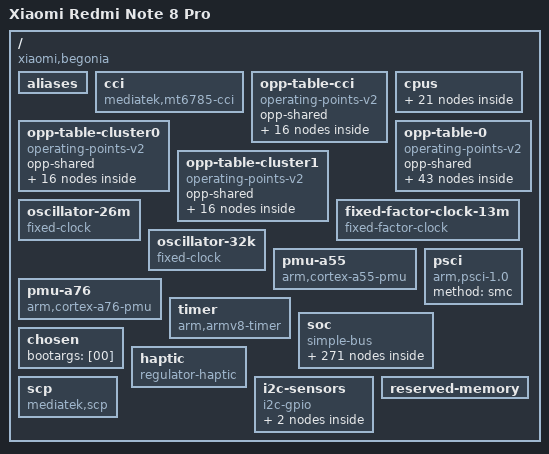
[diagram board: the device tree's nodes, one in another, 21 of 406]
/dts-v1/;

/ {
	#address-cells = <0x02>;
	#size-cells = <0x02>;
	interrupt-parent = <0x01>;
	model = "Xiaomi Redmi Note 8 Pro";
	compatible = "xiaomi,begonia", "mediatek,mt6785";
	chassis-type = "handset";

	aliases {
		ovl0 = "/soc/ovl@14008000";
		ovl-2l0 = "/soc/ovl@14009000";
		ovl-2l1 = "/soc/ovl@1400a000";
		rdma0 = "/soc/rdma@1400b000";
		rdma1 = "/soc/rdma@1400c000";
	};

	cci {
		compatible = "mediatek,mt6785-cci", "mediatek,mt8186-cci";
		clocks = <0x02 0x02 0x03 0x80>;
		clock-names = "cci", "intermediate";
		operating-points-v2 = <0x04>;
		proc-supply = <0x05>;
		phandle = <0x20>;
	};

	opp-table-cci {
		compatible = "operating-points-v2";
		opp-shared;
		phandle = <0x04>;

		opp-500000000 {
			opp-hz = <0x00 0x1dcd6500>;
			opp-microvolt = <0x927c0>;
			phandle = <0x06>;
		};

		opp-560000000 {
			opp-hz = <0x00 0x2160ec00>;
			opp-microvolt = <0xa4cb8>;
			phandle = <0x07>;
		};

		opp-612000000 {
			opp-hz = <0x00 0x247a6100>;
			opp-microvolt = <0xa95f6>;
			phandle = <0x08>;
		};

		opp-682000000 {
			opp-hz = <0x00 0x28a67e80>;
			opp-microvolt = <0xaf79e>;
			phandle = <0x09>;
		};

		opp-752000000 {
			opp-hz = <0x00 0x2cd29c00>;
			opp-microvolt = <0xb5946>;
			phandle = <0x0a>;
		};

		opp-822000000 {
			opp-hz = <0x00 0x30feb980>;
			opp-microvolt = <0xbbaee>;
			phandle = <0x0b>;
		};

		opp-875000000 {
			opp-hz = <0x00 0x342770c0>;
			opp-microvolt = <0xbebc2>;
			phandle = <0x0c>;
		};

		opp-927000000 {
			opp-hz = <0x00 0x3740e5c0>;
			opp-microvolt = "", "\f5";
			phandle = <0x0d>;
		};

		opp-980000000 {
			opp-hz = <0x00 0x3a699d00>;
			opp-microvolt = <0xc7e3e>;
			phandle = <0x0e>;
		};

		opp-1050000000 {
			opp-hz = <0x00 0x3e95ba80>;
			opp-microvolt = <0xcdfe6>;
			phandle = <0x0f>;
		};

		opp-1120000000 {
			opp-hz = <0x00 0x42c1d800>;
			opp-microvolt = <0xd2924>;
			phandle = <0x10>;
		};

		opp-1155000000 {
			opp-hz = <0x00 0x44d7e6c0>;
			opp-microvolt = <0xd8acc>;
			phandle = <0x11>;
		};

		opp-1190000000 {
			opp-hz = <0x00 0x46edf580>;
			opp-microvolt = <0xdd40a>;
			phandle = <0x12>;
		};

		opp-1260000000 {
			opp-hz = <0x00 0x4b1a1300>;
			opp-microvolt = <0xe7ef0>;
			phandle = <0x13>;
		};

		opp-1330000000 {
			opp-hz = <0x00 0x4f463080>;
			opp-microvolt = <0xf29d6>;
			phandle = <0x14>;
		};

		opp-1400000000 {
			opp-hz = <0x00 0x53724e00>;
			opp-microvolt = <0xfbc52>;
			phandle = <0x15>;
		};
	};

	opp-table-cluster0 {
		compatible = "operating-points-v2";
		opp-shared;
		phandle = <0x1e>;

		opp-500000000 {
			opp-hz = <0x00 0x1dcd6500>;
			opp-microvolt = <0x927c0>;
			required-opps = <0x06>;
		};

		opp-774000000 {
			opp-hz = <0x00 0x2e224d80>;
			opp-microvolt = <0xa4cb8>;
			required-opps = <0x07>;
		};

		opp-875000000 {
			opp-hz = <0x00 0x342770c0>;
			opp-microvolt = <0xaae60>;
			required-opps = <0x08>;
		};

		opp-975000000 {
			opp-hz = <0x00 0x3a1d51c0>;
			opp-microvolt = <0xb1008>;
			required-opps = <0x09>;
		};

		opp-1075000000 {
			opp-hz = <0x00 0x401332c0>;
			opp-microvolt = <0xb71b0>;
			required-opps = <0x0a>;
		};

		opp-1175000000 {
			opp-hz = <0x00 0x460913c0>;
			opp-microvolt = <0xbd358>;
			required-opps = <0x0b>;
		};

		opp-1275000000 {
			opp-hz = <0x00 0x4bfef4c0>;
			opp-microvolt = "", "\f5";
			required-opps = <0x0c>;
		};

		opp-1375000000 {
			opp-hz = <0x00 0x51f4d5c0>;
			opp-microvolt = <0xc96a8>;
			required-opps = <0x0d>;
		};

		opp-1500000000 {
			opp-hz = <0x00 0x59682f00>;
			opp-microvolt = <0xd10ba>;
			required-opps = <0x0e>;
		};

		opp-1618000000 {
			opp-hz = <0x00 0x6070b880>;
			opp-microvolt = <0xd59f8>;
			required-opps = <0x0f>;
		};

		opp-1666000000 {
			opp-hz = <0x00 0x634d2480>;
			opp-microvolt = <0xdbba0>;
			required-opps = <0x10>;
		};

		opp-1733000000 {
			opp-hz = <0x00 0x674b7b40>;
			opp-microvolt = <0xe1d48>;
			required-opps = <0x11>;
		};

		opp-1800000000 {
			opp-hz = <0x00 0x6b49d200>;
			opp-microvolt = <0xe7ef0>;
			required-opps = <0x12>;
		};

		opp-1866000000 {
			opp-hz = <0x00 0x6f38e680>;
			opp-microvolt = <0xef902>;
			required-opps = <0x13>;
		};

		opp-1933000000 {
			opp-hz = <0x00 0x73373d40>;
			opp-microvolt = <0xf5aaa>;
			required-opps = <0x14>;
		};

		opp-2000000000 {
			opp-hz = <0x00 0x77359400>;
			opp-microvolt = <0xfbc52>;
			required-opps = <0x15>;
		};
	};

	opp-table-cluster1 {
		compatible = "operating-points-v2";
		opp-shared;
		phandle = <0x21>;

		opp-774000000 {
			opp-hz = <0x00 0x2e224d80>;
			opp-microvolt = <0xa4cb8>;
			required-opps = <0x06>;
		};

		opp-835000000 {
			opp-hz = <0x00 0x31c516c0>;
			opp-microvolt = <0xa95f6>;
			required-opps = <0x07>;
		};

		opp-919000000 {
			opp-hz = <0x00 0x36c6d3c0>;
			opp-microvolt = <0xaf79e>;
			required-opps = <0x08>;
		};

		opp-1002000000 {
			opp-hz = <0x00 0x3bb94e80>;
			opp-microvolt = <0xb5946>;
			required-opps = <0x09>;
		};

		opp-1085000000 {
			opp-hz = <0x00 0x40abc940>;
			opp-microvolt = <0xbd358>;
			required-opps = <0x0a>;
		};

		opp-1169000000 {
			opp-hz = <0x00 0x45ad8640>;
			opp-microvolt = "", "\f5";
			required-opps = <0x0b>;
		};

		opp-1308000000 {
			opp-hz = <0x00 0x4df67f00>;
			opp-microvolt = <0xcdfe6>;
			required-opps = <0x0c>;
		};

		opp-1419000000 {
			opp-hz = <0x00 0x549438c0>;
			opp-microvolt = <0xd59f8>;
			required-opps = <0x0d>;
		};

		opp-1530000000 {
			opp-hz = <0x00 0x5b31f280>;
			opp-microvolt = <0xdec74>;
			required-opps = <0x0e>;
		};

		opp-1670000000 {
			opp-hz = <0x00 0x638a2d80>;
			opp-microvolt = <0xe975a>;
			required-opps = <0x0f>;
		};

		opp-1733000000 {
			opp-hz = <0x00 0x674b7b40>;
			opp-microvolt = <0xef902>;
			required-opps = <0x10>;
		};

		opp-1796000000 {
			opp-hz = <0x00 0x6b0cc900>;
			opp-microvolt = <0xf7314>;
			required-opps = <0x11>;
		};

		opp-1860000000 {
			opp-hz = <0x00 0x6edd5900>;
			opp-microvolt = <0xfd4bc>;
			required-opps = <0x12>;
		};

		opp-1923000000 {
			opp-hz = <0x00 0x729ea6c0>;
			opp-microvolt = <0x103664>;
			required-opps = <0x13>;
		};

		opp-1986000000 {
			opp-hz = <0x00 0x765ff480>;
			opp-microvolt = <0x10b076>;
			required-opps = <0x14>;
		};

		opp-2050000000 {
			opp-hz = <0x00 0x7a308480>;
			opp-microvolt = <0x11121e>;
			required-opps = <0x15>;
		};
	};

	cpus {
		#address-cells = <0x01>;
		#size-cells = <0x00>;

		cpu-map {

			cluster0 {

				core0 {
					cpu = <0x16>;
				};

				core1 {
					cpu = <0x17>;
				};

				core2 {
					cpu = <0x18>;
				};

				core3 {
					cpu = <0x19>;
				};

				core4 {
					cpu = <0x1a>;
				};

				core5 {
					cpu = <0x1b>;
				};

				core6 {
					cpu = <0x1c>;
				};

				core7 {
					cpu = <0x1d>;
				};
			};
		};

		cpu@0 {
			device_type = "cpu";
			compatible = "arm,cortex-a55";
			reg = <0x00>;
			enable-method = "psci";
			clocks = <0x02 0x00 0x03 0x80>;
			clock-names = "cpu", "intermediate";
			operating-points-v2 = <0x1e>;
			dynamic-power-coefficient = <0x54>;
			capacity-dmips-mhz = <0x11c>;
			i-cache-size = <0x8000>;
			i-cache-line-size = <0x40>;
			i-cache-sets = <0x80>;
			d-cache-size = <0x8000>;
			d-cache-line-size = <0x40>;
			d-cache-sets = <0x80>;
			next-level-cache = <0x1f>;
			mediatek,cci = <0x20>;
			proc-supply = <0x05>;
			phandle = <0x16>;
		};

		cpu@100 {
			device_type = "cpu";
			compatible = "arm,cortex-a55";
			reg = <0x100>;
			enable-method = "psci";
			clocks = <0x02 0x00 0x03 0x80>;
			clock-names = "cpu", "intermediate";
			operating-points-v2 = <0x1e>;
			dynamic-power-coefficient = <0x54>;
			capacity-dmips-mhz = <0x11c>;
			i-cache-size = <0x8000>;
			i-cache-line-size = <0x40>;
			i-cache-sets = <0x80>;
			d-cache-size = <0x8000>;
			d-cache-line-size = <0x40>;
			d-cache-sets = <0x80>;
			next-level-cache = <0x1f>;
			mediatek,cci = <0x20>;
			proc-supply = <0x05>;
			phandle = <0x17>;
		};

		cpu@200 {
			device_type = "cpu";
			compatible = "arm,cortex-a55";
			reg = <0x200>;
			enable-method = "psci";
			clocks = <0x02 0x00 0x03 0x80>;
			clock-names = "cpu", "intermediate";
			operating-points-v2 = <0x1e>;
			dynamic-power-coefficient = <0x54>;
			capacity-dmips-mhz = <0x11c>;
			i-cache-size = <0x8000>;
			i-cache-line-size = <0x40>;
			i-cache-sets = <0x80>;
			d-cache-size = <0x8000>;
			d-cache-line-size = <0x40>;
			d-cache-sets = <0x80>;
			next-level-cache = <0x1f>;
			mediatek,cci = <0x20>;
			proc-supply = <0x05>;
			phandle = <0x18>;
		};

		cpu@300 {
			device_type = "cpu";
			compatible = "arm,cortex-a55";
			reg = <0x300>;
			enable-method = "psci";
			clocks = <0x02 0x00 0x03 0x80>;
			clock-names = "cpu", "intermediate";
			operating-points-v2 = <0x1e>;
			dynamic-power-coefficient = <0x54>;
			capacity-dmips-mhz = <0x11c>;
			i-cache-size = <0x8000>;
			i-cache-line-size = <0x40>;
			i-cache-sets = <0x80>;
			d-cache-size = <0x8000>;
			d-cache-line-size = <0x40>;
			d-cache-sets = <0x80>;
			next-level-cache = <0x1f>;
			mediatek,cci = <0x20>;
			proc-supply = <0x05>;
			phandle = <0x19>;
		};

		cpu@400 {
			device_type = "cpu";
			compatible = "arm,cortex-a55";
			reg = <0x400>;
			enable-method = "psci";
			clocks = <0x02 0x00 0x03 0x80>;
			clock-names = "cpu", "intermediate";
			operating-points-v2 = <0x1e>;
			dynamic-power-coefficient = <0x54>;
			capacity-dmips-mhz = <0x11c>;
			i-cache-size = <0x8000>;
			i-cache-line-size = <0x40>;
			i-cache-sets = <0x80>;
			d-cache-size = <0x8000>;
			d-cache-line-size = <0x40>;
			d-cache-sets = <0x80>;
			next-level-cache = <0x1f>;
			mediatek,cci = <0x20>;
			proc-supply = <0x05>;
			phandle = <0x1a>;
		};

		cpu@500 {
			device_type = "cpu";
			compatible = "arm,cortex-a55";
			reg = <0x500>;
			enable-method = "psci";
			clocks = <0x02 0x00 0x03 0x80>;
			clock-names = "cpu", "intermediate";
			operating-points-v2 = <0x1e>;
			dynamic-power-coefficient = <0x54>;
			capacity-dmips-mhz = <0x11c>;
			i-cache-size = <0x8000>;
			i-cache-line-size = <0x40>;
			i-cache-sets = <0x80>;
			d-cache-size = <0x8000>;
			d-cache-line-size = <0x40>;
			d-cache-sets = <0x80>;
			next-level-cache = <0x1f>;
			mediatek,cci = <0x20>;
			proc-supply = <0x05>;
			phandle = <0x1b>;
		};

		cpu@600 {
			device_type = "cpu";
			compatible = "arm,cortex-a76";
			reg = <0x600>;
			enable-method = "psci";
			clocks = <0x02 0x01 0x03 0x80>;
			clock-names = "cpu", "intermediate";
			operating-points-v2 = <0x21>;
			dynamic-power-coefficient = <0x113>;
			capacity-dmips-mhz = <0x400>;
			i-cache-size = <0x10000>;
			i-cache-line-size = <0x40>;
			i-cache-sets = <0x100>;
			d-cache-size = <0x10000>;
			d-cache-line-size = <0x40>;
			d-cache-sets = <0x100>;
			next-level-cache = <0x22>;
			mediatek,cci = <0x20>;
			proc-supply = <0x23>;
			phandle = <0x1c>;
		};

		cpu@700 {
			device_type = "cpu";
			compatible = "arm,cortex-a76";
			reg = <0x700>;
			enable-method = "psci";
			clocks = <0x02 0x01 0x03 0x80>;
			clock-names = "cpu", "intermediate";
			operating-points-v2 = <0x21>;
			dynamic-power-coefficient = <0x113>;
			capacity-dmips-mhz = <0x400>;
			i-cache-size = <0x10000>;
			i-cache-line-size = <0x40>;
			i-cache-sets = <0x100>;
			d-cache-size = <0x10000>;
			d-cache-line-size = <0x40>;
			d-cache-sets = <0x100>;
			next-level-cache = <0x22>;
			mediatek,cci = <0x20>;
			proc-supply = <0x23>;
			phandle = <0x1d>;
		};

		l2-cache0 {
			compatible = "cache";
			cache-level = <0x02>;
			cache-size = <0x20000>;
			cache-line-size = <0x40>;
			cache-sets = <0x200>;
			next-level-cache = <0x24>;
			cache-unified;
			phandle = <0x1f>;
		};

		l2-cache1 {
			compatible = "cache";
			cache-level = <0x02>;
			cache-size = <0x40000>;
			cache-line-size = <0x40>;
			cache-sets = <0x200>;
			next-level-cache = <0x24>;
			cache-unified;
			phandle = <0x22>;
		};

		l3-cache {
			compatible = "cache";
			cache-level = <0x03>;
			cache-size = <0x100000>;
			cache-line-size = <0x40>;
			cache-sets = <0x400>;
			cache-unified;
			phandle = <0x24>;
		};
	};

	opp-table-0 {
		compatible = "operating-points-v2";
		opp-shared;
		phandle = <0x54>;

		opp-270000000 {
			opp-hz = <0x00 0x1017df80>;
			opp-microvolt = <0x95894>;
		};

		opp-295000000 {
			opp-hz = <0x00 0x119557c0>;
			opp-microvolt = <0x970fe>;
		};

		opp-320000000 {
			opp-hz = <0x00 0x1312d000>;
			opp-microvolt = <0x98968>;
		};

		opp-345000000 {
			opp-hz = <0x00 0x14904840>;
			opp-microvolt = <0x9a1d2>;
		};

		opp-370000000 {
			opp-hz = <0x00 0x160dc080>;
			opp-microvolt = <0x9ba3c>;
		};

		opp-395000000 {
			opp-hz = <0x00 0x178b38c0>;
			opp-microvolt = <0x9d2a6>;
		};

		opp-420000000 {
			opp-hz = <0x00 0x1908b100>;
			opp-microvolt = <0x9eb10>;
		};

		opp-445000000 {
			opp-hz = <0x00 0x1a862940>;
			opp-microvolt = <0xa037a>;
		};

		opp-470000000 {
			opp-hz = <0x00 0x1c03a180>;
			opp-microvolt = <0xa1be4>;
		};

		opp-495000000 {
			opp-hz = <0x00 0x1d8119c0>;
			opp-microvolt = <0xa344e>;
		};

		opp-520000000 {
			opp-hz = <0x00 0x1efe9200>;
			opp-microvolt = <0xa4cb8>;
		};

		opp-545000000 {
			opp-hz = <0x00 0x207c0a40>;
			opp-microvolt = <0xa6522>;
		};

		opp-570000000 {
			opp-hz = <0x00 0x21f98280>;
			opp-microvolt = <0xa7d8c>;
		};

		opp-595000000 {
			opp-hz = <0x00 0x2376fac0>;
			opp-microvolt = <0xa95f6>;
		};

		opp-620000000 {
			opp-hz = <0x00 0x24f47300>;
			opp-microvolt = <0xaae60>;
		};

		opp-634000000 {
			opp-hz = <0x00 0x25ca1280>;
			opp-microvolt = <0xac6ca>;
		};

		opp-648000000 {
			opp-hz = <0x00 0x269fb200>;
			opp-microvolt = <0xadf34>;
		};

		opp-663000000 {
			opp-hz = <0x00 0x278493c0>;
			opp-microvolt = <0xaf79e>;
		};

		opp-677000000 {
			opp-hz = <0x00 0x285a3340>;
			opp-microvolt = <0xb1008>;
		};

		opp-691000000 {
			opp-hz = <0x00 0x292fd2c0>;
			opp-microvolt = <0xb2872>;
		};

		opp-706000000 {
			opp-hz = <0x00 0x2a14b480>;
			opp-microvolt = <0xb40dc>;
		};

		opp-720000000 {
			opp-hz = <0x00 0x2aea5400>;
			opp-microvolt = <0xb5946>;
		};

		opp-735000000 {
			opp-hz = <0x00 0x2bcf35c0>;
			opp-microvolt = <0xb71b0>;
		};

		opp-749000000 {
			opp-hz = <0x00 0x2ca4d540>;
			opp-microvolt = <0xb8a1a>;
		};

		opp-763000000 {
			opp-hz = <0x00 0x2d7a74c0>;
			opp-microvolt = <0xba284>;
		};

		opp-778000000 {
			opp-hz = <0x00 0x2e5f5680>;
			opp-microvolt = <0xbbaee>;
		};

		opp-792000000 {
			opp-hz = <0x00 0x2f34f600>;
			opp-microvolt = <0xbd358>;
		};

		opp-806000000 {
			opp-hz = <0x00 0x300a9580>;
			opp-microvolt = <0xbebc2>;
		};

		opp-821000000 {
			opp-hz = <0x00 0x30ef7740>;
			opp-microvolt = <0xc042c>;
		};

		opp-835000000 {
			opp-hz = <0x00 0x31c516c0>;
			opp-microvolt = <0xc1c96>;
		};

		opp-850000000 {
			opp-hz = <0x00 0x32a9f880>;
			opp-microvolt = "", "\f5";
		};

		opp-854000000 {
			opp-hz = <0x00 0x32e70180>;
			opp-microvolt = <0xc4d6a>;
		};

		opp-858000000 {
			opp-hz = <0x00 0x33240a80>;
			opp-microvolt = <0xc65d4>;
		};

		opp-862000000 {
			opp-hz = <0x00 0x33611380>;
			opp-microvolt = <0xc7e3e>;
		};

		opp-867000000 {
			opp-hz = <0x00 0x33ad5ec0>;
			opp-microvolt = <0xc96a8>;
		};

		opp-871000000 {
			opp-hz = <0x00 0x33ea67c0>;
			opp-microvolt = <0xcaf12>;
		};

		opp-875000000 {
			opp-hz = <0x00 0x342770c0>;
			opp-microvolt = <0xcc77c>;
		};

		opp-880000000 {
			opp-hz = <0x00 0x3473bc00>;
			opp-microvolt = <0xcdfe6>;
		};

		opp-884000000 {
			opp-hz = <0x00 0x34b0c500>;
			opp-microvolt = <0xcf850>;
		};

		opp-888000000 {
			opp-hz = <0x00 0x34edce00>;
			opp-microvolt = <0xd10ba>;
		};

		opp-892000000 {
			opp-hz = <0x00 0x352ad700>;
			opp-microvolt = <0xd2924>;
		};

		opp-897000000 {
			opp-hz = <0x00 0x35772240>;
			opp-microvolt = <0xd418e>;
		};

		opp-900000000 {
			opp-hz = <0x00 0x35a4e900>;
			opp-microvolt = <0xd59f8>;
		};
	};

	fixed-factor-clock-13m {
		compatible = "fixed-factor-clock";
		#clock-cells = <0x00>;
		clocks = <0x25>;
		clock-div = <0x02>;
		clock-mult = <0x01>;
		clock-output-names = "clk13m";
		phandle = <0x30>;
	};

	oscillator-26m {
		compatible = "fixed-clock";
		#clock-cells = <0x00>;
		clock-frequency = <0x18cba80>;
		clock-output-names = "clk26m";
		phandle = <0x25>;
	};

	oscillator-32k {
		compatible = "fixed-clock";
		#clock-cells = <0x00>;
		clock-frequency = <0x8000>;
		clock-output-names = "clk32k";
	};

	pmu-a55 {
		compatible = "arm,cortex-a55-pmu";
		interrupt-parent = <0x26>;
		interrupts = <0x01 0x07 0x08 0x27>;
	};

	pmu-a76 {
		compatible = "arm,cortex-a76-pmu";
		interrupt-parent = <0x26>;
		interrupts = <0x01 0x07 0x08 0x28>;
	};

	psci {
		compatible = "arm,psci-1.0";
		method = "smc";
	};

	timer {
		compatible = "arm,armv8-timer";
		interrupt-parent = <0x26>;
		interrupts = <0x01 0x0d 0x08 0x00 0x01 0x0e 0x08 0x00 0x01 0x0b 0x08 0x00 0x01 0x0a 0x08 0x00>;
	};

	soc {
		#address-cells = <0x02>;
		#size-cells = <0x02>;
		compatible = "simple-bus";
		ranges;

		interrupt-controller@c000000 {
			compatible = "arm,gic-v3";
			#interrupt-cells = <0x04>;
			#redistributor-regions = <0x01>;
			interrupt-parent = <0x26>;
			interrupt-controller;
			reg = <0x00 0xc000000 0x00 0x40000 0x00 0xc040000 0x00 0x200000>;
			interrupts = <0x01 0x09 0x04 0x00>;
			phandle = <0x26>;

			ppi-partitions {

				interrupt-partition-0 {
					affinity = <0x16 0x17 0x18 0x19 0x1a 0x1b>;
					phandle = <0x27>;
				};

				interrupt-partition-1 {
					affinity = <0x1c 0x1d>;
					phandle = <0x28>;
				};
			};
		};

		clock-controller@c53a000 {
			compatible = "mediatek,mt6785-mcusys", "syscon";
			reg = <0x00 0xc53a000 0x00 0x1000>;
			#clock-cells = <0x01>;
			phandle = <0x02>;
		};

		interrupt-controller@c53a650 {
			compatible = "mediatek,mt6785-sysirq", "mediatek,mt6577-sysirq";
			interrupt-controller;
			#interrupt-cells = <0x03>;
			interrupt-parent = <0x26>;
			reg = <0x00 0xc53a650 0x00 0x50>;
			phandle = <0x01>;
		};

		clock-controller@10000000 {
			compatible = "mediatek,mt6785-topckgen", "syscon";
			reg = <0x00 0x10000000 0x00 0x1000>;
			#clock-cells = <0x01>;
			phandle = <0x03>;
		};

		clock-controller@10001000 {
			compatible = "mediatek,mt6785-infracfg", "syscon";
			reg = <0x00 0x10001000 0x00 0x1000>;
			#clock-cells = <0x01>;
			#reset-cells = <0x01>;
			phandle = <0x2a>;
		};

		syscon@10003000 {
			compatible = "mediatek,mt6785-pericfg", "syscon";
			reg = <0x00 0x10003000 0x00 0x1000>;
			phandle = <0x46>;
		};

		pinctrl@10005000 {
			compatible = "mediatek,mt6785-pinctrl";
			reg = <0x00 0x10005000 0x00 0x1000 0x00 0x11c20000 0x00 0x1000 0x00 0x11d10000 0x00 0x1000 0x00 0x11e20000 0x00 0x1000 0x00 0x11e70000 0x00 0x1000 0x00 0x11ea0000 0x00 0x1000 0x00 0x11f20000 0x00 0x1000 0x00 0x11f30000 0x00 0x1000 0x00 0x1000b000 0x00 0x1000>;
			reg-names = "base", "rm", "br", "bl", "lb", "rt", "lt", "tl", "eint";
			interrupts = <0x00 0xcc 0x04>;
			gpio-controller;
			#gpio-cells = <0x02>;
			gpio-ranges = <0x29 0x00 0x00 0xca>;
			interrupt-controller;
			#interrupt-cells = <0x02>;
			phandle = <0x29>;

			backlight-pins {
				phandle = <0x38>;

				pins-enable {
					pinmux = <0x1600>;
					output-high;
				};
			};

			i2c0-pins {
				phandle = <0x37>;

				pins-bus {
					pinmux = <0x3301 0x3401>;
					bias-pull-up;
				};
			};

			i2c1-pins {
				phandle = <0x79>;

				pins-bus {
					pinmux = <0x3d01 0x3e01>;
					bias-pull-up;
				};
			};

			i2c3-pins {
				phandle = <0x39>;

				pins-bus {
					pinmux = <0x3701 0x3801>;
					bias-pull-up;
				};
			};

			i2c5-pins {
				phandle = <0x3d>;

				pins-bus {
					pinmux = <0x1c01 0x1d01>;
					bias-pull-up;
				};
			};

			imu-pins {
				phandle = <0x3c>;

				pins-interrupt {
					pinmux = <0xa00>;
					bias-pull-down = <0x64>;
					input-enable;
				};
			};

			keypad-pins {
				phandle = <0x2f>;

				pins-volume {
					pinmux = <0x3b01 0x3c01>;
					input-enable;
				};
			};

			mmc1-pins {
				phandle = <0x4c>;

				pins-cmd-dat {
					pinmux = <0x8701 0x8901 0x8b01 0x8a01 0x8801>;
					bias-pull-up = <0x65>;
					drive-strength = <0x08>;
					input-enable;
				};

				pins-clk {
					pinmux = <0x8601>;
					bias-pull-down = <0x66>;
					drive-strength = <0x08>;
				};
			};

			mmc1-pins-detect {
				phandle = <0x4d>;

				pins-insert {
					pinmux = <0x800>;
					bias-pull-up;
					input-enable;
				};
			};

			mt6360-pins {
				phandle = <0x3e>;

				pins-interrupt {
					pinmux = <0x700 0x1000>;
					bias-pull-up;
					input-enable;
				};
			};

			panel-pins {
				phandle = <0x70>;

				pins-reset {
					pinmux = <0x2c00>;
				};
			};

			proximity-pins {
				phandle = <0x7a>;

				pins-interrupt {
					pinmux = <0x600>;
					bias-pull-up;
					input-enable;
				};
			};

			spi2-pins {
				phandle = <0x3a>;

				pins-bus {
					pinmux = <0x3f01 0x4001 0x4101 0x4201>;
					bias-disable;
				};
			};

			spi5-pins {
				phandle = <0x41>;

				pins-bus {
					pinmux = <0x2505 0x2405 0x2305 0x2605>;
					bias-disable;
				};
			};

			touchscreen-pins {
				phandle = <0x43>;

				pins-interrupt {
					pinmux = <0x100>;
					bias-pull-up;
					input-enable;
				};

				pins-reset {
					pinmux = <0x200>;
				};
			};
		};

		syscon@10006000 {
			compatible = "mediatek,mt6785-scpsys", "syscon", "simple-mfd";
			reg = <0x00 0x10006000 0x00 0x1000>;

			power-controller {
				compatible = "mediatek,mt6785-power-controller";
				#address-cells = <0x01>;
				#size-cells = <0x00>;
				#power-domain-cells = <0x01>;
				phandle = <0x55>;

				power-domain@0 {
					reg = <0x00>;
					clocks = <0x2a 0x36>;
					clock-names = "audio";
					mediatek,infracfg = <0x2a>;
					#power-domain-cells = <0x00>;
				};

				power-domain@2 {
					reg = <0x02>;
					mediatek,infracfg = <0x2a>;
					mediatek,smi = <0x2b>;
					#power-domain-cells = <0x00>;
				};

				power-domain@4 {
					reg = <0x04>;
					mediatek,infracfg = <0x2a>;
					#power-domain-cells = <0x00>;
				};

				power-domain@6 {
					reg = <0x06>;
					clocks = <0x03 0x4a>;
					clock-names = "mfg";
					#address-cells = <0x01>;
					#size-cells = <0x00>;
					#power-domain-cells = <0x01>;
					domain-supply = <0x2c>;

					power-domain@5 {
						reg = <0x05>;
						mediatek,infracfg = <0x2a>;
						#address-cells = <0x01>;
						#size-cells = <0x00>;
						#power-domain-cells = <0x01>;
						domain-supply = <0x2d>;

						power-domain@7 {
							reg = <0x07>;
							#power-domain-cells = <0x00>;
						};

						power-domain@8 {
							reg = <0x08>;
							#power-domain-cells = <0x00>;
						};

						power-domain@9 {
							reg = <0x09>;
							#power-domain-cells = <0x00>;
						};

						power-domain@10 {
							reg = <0x0a>;
							#power-domain-cells = <0x00>;
						};
					};
				};

				power-domain@11 {
					reg = <0x0b>;
					clocks = <0x03 0x3f>;
					clock-names = "mm";
					mediatek,infracfg-nao = <0x2e>;
					mediatek,infracfg = <0x2a>;
					mediatek,smi = <0x2b>;
					#address-cells = <0x01>;
					#size-cells = <0x00>;
					#power-domain-cells = <0x01>;

					power-domain@1 {
						reg = <0x01>;
						clocks = <0x03 0x44>;
						clock-names = "cam";
						mediatek,infracfg = <0x2a>;
						mediatek,smi = <0x2b>;
						#power-domain-cells = <0x00>;
					};

					power-domain@3 {
						reg = <0x03>;
						clocks = <0x03 0x41>;
						clock-names = "isp";
						mediatek,infracfg = <0x2a>;
						mediatek,smi = <0x2b>;
						#power-domain-cells = <0x00>;
					};

					power-domain@12 {
						reg = <0x0c>;
						clocks = <0x03 0x6e>;
						clock-names = "vdec";
						mediatek,infracfg = <0x2a>;
						mediatek,smi = <0x2b>;
						#power-domain-cells = <0x00>;
					};

					power-domain@13 {
						reg = <0x0d>;
						clocks = <0x03 0x6d>;
						clock-names = "venc";
						mediatek,infracfg = <0x2a>;
						mediatek,smi = <0x2b>;
						#power-domain-cells = <0x00>;
					};
				};
			};
		};

		watchdog@10007000 {
			compatible = "mediatek,mt6785-wdt";
			reg = <0x00 0x10007000 0x00 0x1000>;
			interrupts = <0x00 0x48 0x08>;
			#reset-cells = <0x01>;
		};

		clock-controller@1000c000 {
			compatible = "mediatek,mt6785-apmixedsys", "syscon";
			reg = <0x00 0x1000c000 0x00 0x1000>;
			#clock-cells = <0x01>;
			phandle = <0x52>;
		};

		pwrap@1000d000 {
			compatible = "mediatek,mt6785-pwrap";
			reg = <0x00 0x1000d000 0x00 0x1000>;
			reg-names = "pwrap";
			interrupts = <0x00 0xd4 0x04>;
			clocks = <0x2a 0x01 0x2a 0x00>;
			clock-names = "spi", "wrap";
			resets = <0x2a 0x02>;
			reset-names = "pwrap";

			pmic {
				compatible = "mediatek,mt6359";
				interrupt-controller;
				#interrupt-cells = <0x02>;
				#sound-dai-cells = <0x01>;
				interrupts-extended = <0x29 0xc1 0x04>;

				adc {
					compatible = "mediatek,mt6359-auxadc";
					#io-channel-cells = <0x01>;
				};

				audio-codec {
					compatible = "mediatek,mt6359-codec";
				};

				regulators {
					compatible = "mediatek,mt6359-regulator";

					buck_vs1 {
						regulator-name = "vs1";
						regulator-min-microvolt = "", "\f5";
						regulator-max-microvolt = <0x2191c0>;
						regulator-enable-ramp-delay = <0x00>;
						regulator-always-on;
					};

					buck_vgpu11 {
						regulator-name = "vgpu";
						regulator-min-microvolt = <0x86470>;
						regulator-max-microvolt = <0xd59f8>;
						regulator-ramp-delay = <0x1388>;
						regulator-enable-ramp-delay = <0xc8>;
						regulator-allowed-modes = <0x00 0x01 0x02>;
						regulator-coupled-with = <0x2d>;
						regulator-coupled-max-spread = <0x186a0>;
						phandle = <0x2c>;
					};

					buck_vmodem {
						regulator-name = "vmodem";
						regulator-min-microvolt = <0x61a80>;
						regulator-max-microvolt = <0x10c8e0>;
						regulator-ramp-delay = <0x2a08>;
						regulator-enable-ramp-delay = <0xc8>;
					};

					buck_vpu {
						regulator-name = "vsram_gpu";
						regulator-min-microvolt = <0xcf850>;
						regulator-max-microvolt = <0xee098>;
						regulator-ramp-delay = <0x1388>;
						regulator-enable-ramp-delay = <0xc8>;
						regulator-allowed-modes = <0x00 0x01 0x02>;
						regulator-coupled-with = <0x2c>;
						regulator-coupled-max-spread = <0x186a0>;
						phandle = <0x2d>;
					};

					buck_vcore {
						regulator-name = "vcore";
						regulator-min-microvolt = <0x61a80>;
						regulator-max-microvolt = <0x13d620>;
						regulator-ramp-delay = <0x1388>;
						regulator-enable-ramp-delay = <0xc8>;
						regulator-allowed-modes = <0x00 0x01 0x02>;
						regulator-always-on;
					};

					buck_vs2 {
						regulator-name = "vs2";
						regulator-min-microvolt = "", "\f5";
						regulator-max-microvolt = <0x186a00>;
						regulator-enable-ramp-delay = <0x00>;
						regulator-always-on;
					};

					buck_vpa {
						regulator-name = "vpa";
						regulator-min-microvolt = <0x7a120>;
						regulator-max-microvolt = <0x37b1d0>;
						regulator-enable-ramp-delay = <0x12c>;
					};

					buck_vproc2 {
						regulator-name = "vproc_l";
						regulator-min-microvolt = <0x61a80>;
						regulator-max-microvolt = <0x123716>;
						regulator-ramp-delay = <0x1d4c>;
						regulator-enable-ramp-delay = <0xc8>;
						regulator-allowed-modes = <0x00 0x01 0x02>;
						regulator-always-on;
						phandle = <0x05>;
					};

					buck_vproc1 {
						regulator-name = "vproc_b";
						regulator-min-microvolt = <0x61a80>;
						regulator-max-microvolt = <0x123716>;
						regulator-ramp-delay = <0x1d4c>;
						regulator-enable-ramp-delay = <0xc8>;
						regulator-allowed-modes = <0x00 0x01 0x02>;
						regulator-always-on;
						phandle = <0x23>;
					};

					buck_vcore_sshub {
						regulator-name = "vcore_sshub";
						regulator-min-microvolt = <0x61a80>;
						regulator-max-microvolt = <0x123716>;
					};

					buck_vgpu11_sshub {
						regulator-name = "vgpu11_sshub";
						regulator-min-microvolt = <0x61a80>;
						regulator-max-microvolt = <0x123716>;
					};

					ldo_vaud18 {
						regulator-name = "vaud18";
						regulator-min-microvolt = <0x1b7740>;
						regulator-max-microvolt = <0x1b7740>;
						regulator-enable-ramp-delay = <0xf0>;
					};

					ldo_vsim1 {
						regulator-name = "vsim1";
						regulator-min-microvolt = <0x19f0a0>;
						regulator-max-microvolt = <0x2f4d60>;
					};

					ldo_vibr {
						regulator-name = "vibr";
						regulator-min-microvolt = <0x124f80>;
						regulator-max-microvolt = <0x325aa0>;
						phandle = <0x78>;
					};

					ldo_vrf12 {
						regulator-name = "vrf12";
						regulator-min-microvolt = <0x10c8e0>;
						regulator-max-microvolt = <0x13d620>;
					};

					ldo_vusb {
						regulator-name = "vusb";
						regulator-min-microvolt = <0x2dc6c0>;
						regulator-max-microvolt = <0x2dc6c0>;
						regulator-enable-ramp-delay = <0x3c0>;
						regulator-always-on;
						phandle = <0x48>;
					};

					ldo_vsram_proc2 {
						regulator-name = "vsram_proc2";
						regulator-min-microvolt = <0x7a120>;
						regulator-max-microvolt = <0x13bdb6>;
						regulator-ramp-delay = <0x1d4c>;
						regulator-enable-ramp-delay = <0xf0>;
						regulator-always-on;
					};

					ldo_vio18 {
						regulator-name = "vio18";
						regulator-min-microvolt = <0x19f0a0>;
						regulator-max-microvolt = <0x1cfde0>;
						regulator-enable-ramp-delay = <0x3c0>;
						regulator-always-on;
						phandle = <0x3b>;
					};

					ldo_vcamio {
						regulator-name = "vcamio";
						regulator-min-microvolt = <0x19f0a0>;
						regulator-max-microvolt = <0x1cfde0>;
					};

					ldo_vcn18 {
						regulator-name = "vcn18";
						regulator-min-microvolt = <0x1b7740>;
						regulator-max-microvolt = <0x1b7740>;
						regulator-enable-ramp-delay = <0xf0>;
					};

					ldo_vfe28 {
						regulator-name = "vfe28";
						regulator-min-microvolt = <0x2ab980>;
						regulator-max-microvolt = <0x2ab980>;
						regulator-enable-ramp-delay = <0x78>;
					};

					ldo_vcn13 {
						regulator-name = "vcn13";
						regulator-min-microvolt = <0xdbba0>;
						regulator-max-microvolt = <0x13d620>;
					};

					ldo_vcn33_1_bt {
						regulator-name = "vcn33_1_bt";
						regulator-min-microvolt = <0x2ab980>;
						regulator-max-microvolt = <0x3567e0>;
					};

					ldo_vcn33_1_wifi {
						regulator-name = "vcn33_1_wifi";
						regulator-min-microvolt = <0x2ab980>;
						regulator-max-microvolt = <0x3567e0>;
					};

					ldo_vaux18 {
						regulator-name = "vaux18";
						regulator-min-microvolt = <0x1b7740>;
						regulator-max-microvolt = <0x1b7740>;
						regulator-enable-ramp-delay = <0xf0>;
						regulator-always-on;
					};

					ldo_vsram_others {
						regulator-name = "vsram_core";
						regulator-min-microvolt = <0x7a120>;
						regulator-max-microvolt = <0x13bdb6>;
						regulator-ramp-delay = <0x1388>;
						regulator-enable-ramp-delay = <0xf0>;
						regulator-always-on;
					};

					ldo_vefuse {
						regulator-name = "vefuse";
						regulator-min-microvolt = <0x19f0a0>;
						regulator-max-microvolt = <0x1e8480>;
					};

					ldo_vxo22 {
						regulator-name = "vxo22";
						regulator-min-microvolt = <0x1b7740>;
						regulator-max-microvolt = <0x2191c0>;
						regulator-always-on;
					};

					ldo_vrfck {
						regulator-name = "vrfck";
						regulator-min-microvolt = <0x16e360>;
						regulator-max-microvolt = <0x19f0a0>;
					};

					ldo_vrfck_1 {
						regulator-name = "vrfck";
						regulator-min-microvolt = <0x12ebc0>;
						regulator-max-microvolt = <0x186a00>;
					};

					ldo_vbif28 {
						regulator-name = "vbif28";
						regulator-min-microvolt = <0x2ab980>;
						regulator-max-microvolt = <0x2ab980>;
						regulator-enable-ramp-delay = <0xf0>;
					};

					ldo_vio28 {
						regulator-name = "vio28";
						regulator-min-microvolt = <0x2ab980>;
						regulator-max-microvolt = <0x325aa0>;
						regulator-always-on;
					};

					ldo_vemc {
						regulator-name = "vemc";
						regulator-min-microvolt = <0x2c4020>;
						regulator-max-microvolt = <0x325aa0>;
						phandle = <0x50>;
					};

					ldo_vemc_1 {
						regulator-name = "vemc";
						regulator-min-microvolt = <0x2625a0>;
						regulator-max-microvolt = <0x325aa0>;
					};

					ldo_vcn33_2_bt {
						regulator-name = "vcn33_2_bt";
						regulator-min-microvolt = <0x2ab980>;
						regulator-max-microvolt = <0x3567e0>;
					};

					ldo_vcn33_2_wifi {
						regulator-name = "vcn33_2_wifi";
						regulator-min-microvolt = <0x2ab980>;
						regulator-max-microvolt = <0x3567e0>;
					};

					ldo_va12 {
						regulator-name = "va12";
						regulator-min-microvolt = <0x124f80>;
						regulator-max-microvolt = <0x13d620>;
						regulator-always-on;
					};

					ldo_va09 {
						regulator-name = "va09";
						regulator-min-microvolt = "", "\f5";
						regulator-max-microvolt = <0x124f80>;
						phandle = <0x4f>;
					};

					ldo_vrf18 {
						regulator-name = "vrf18";
						regulator-min-microvolt = <0x19f0a0>;
						regulator-max-microvolt = <0x1b9e50>;
					};

					ldo_vsram_md {
						regulator-name = "vsram_md";
						regulator-min-microvolt = <0x7a120>;
						regulator-max-microvolt = <0x13bdb6>;
						regulator-ramp-delay = <0x2a08>;
						regulator-enable-ramp-delay = <0xf0>;
					};

					ldo_vufs {
						regulator-name = "vufs";
						regulator-min-microvolt = <0x19f0a0>;
						regulator-max-microvolt = <0x1cfde0>;
						phandle = <0x51>;
					};

					ldo_vm18 {
						regulator-name = "vm18";
						regulator-min-microvolt = <0x19f0a0>;
						regulator-max-microvolt = <0x1cfde0>;
						regulator-always-on;
					};

					ldo_vbbck {
						regulator-name = "vbbck";
						regulator-min-microvolt = <0x10c8e0>;
						regulator-max-microvolt = <0x124f80>;
					};

					ldo_vsram_proc1 {
						regulator-name = "vsram_proc1";
						regulator-min-microvolt = <0x7a120>;
						regulator-max-microvolt = <0x13bdb6>;
						regulator-ramp-delay = <0x1d4c>;
						regulator-enable-ramp-delay = <0xf0>;
						regulator-always-on;
					};

					ldo_vsim2 {
						regulator-name = "vsim2";
						regulator-min-microvolt = <0x19f0a0>;
						regulator-max-microvolt = <0x2f4d60>;
					};

					ldo_vsram_others_sshub {
						regulator-name = "vsram_others_sshub";
						regulator-min-microvolt = <0x7a120>;
						regulator-max-microvolt = <0x13bdb6>;
					};
				};

				rtc {
					compatible = "mediatek,mt6358-rtc";
				};

				keys {
					compatible = "mediatek,mt6359-keys";

					power {
						linux,keycodes = <0x74>;
						wakeup-source;
					};
				};
			};
		};

		keypad@10010000 {
			compatible = "mediatek,mt6785-keypad", "mediatek,mt6779-keypad";
			reg = <0x00 0x10010000 0x00 0x1000>;
			interrupts = <0x00 0x4b 0x02>;
			clocks = <0x25>;
			clock-names = "kpd";
			status = "okay";
			linux,keymap = <0x73 0x10072>;
			keypad,num-rows = <0x01>;
			keypad,num-columns = <0x02>;
			debounce-delay-ms = <0x20>;
			pinctrl-names = "default";
			pinctrl-0 = <0x2f>;
		};

		timer@10017000 {
			compatible = "mediatek,mt6785-timer", "mediatek,mt6765-timer";
			reg = <0x00 0x10017000 0x00 0x1000>;
			interrupts = <0x00 0xe0 0x04>;
			clocks = <0x30>;
		};

		infracfg@1020e000 {
			compatible = "mediatek,mt6785-infracfg-nao", "syscon";
			reg = <0x00 0x1020e000 0x00 0x1000>;
			#clock-cells = <0x01>;
			phandle = <0x2e>;
		};

		iommu@10220000 {
			compatible = "mediatek,mt6785-iommu-mm";
			reg = <0x00 0x10220000 0x00 0x4000>;
			interrupts = <0x00 0xbb 0x08>;
			mediatek,larbs = <0x31 0x32 0x33 0x34 0x35 0x36>;
			#iommu-cells = <0x01>;
			phandle = <0x59>;
		};

		mailbox@10228000 {
			compatible = "mediatek,mt6785-gce", "mediatek,mt6779-gce";
			reg = <0x00 0x10228000 0x00 0x4000>;
			clocks = <0x2a 0x08>;
			clock-names = "gce";
			interrupts = <0x00 0xb9 0x08>;
			#mbox-cells = <0x02>;
			phandle = <0x56>;
		};

		serial@11002000 {
			compatible = "mediatek,mt6785-uart", "mediatek,mt6577-uart";
			reg = <0x00 0x11002000 0x00 0x1000>;
			interrupts = <0x00 0x73 0x08>;
			clocks = <0x25 0x2a 0x14>;
			clock-names = "baud", "bus";
			status = "disabled";
		};

		serial@11003000 {
			compatible = "mediatek,mt6785-uart", "mediatek,mt6577-uart";
			reg = <0x00 0x11003000 0x00 0x1000>;
			interrupts = <0x00 0x74 0x08>;
			clocks = <0x25 0x2a 0x15>;
			clock-names = "baud", "bus";
			status = "disabled";
		};

		i2c@11005000 {
			compatible = "mediatek,mt6785-i2c", "mediatek,mt8183-i2c";
			reg = <0x00 0x11005000 0x00 0x1000 0x00 0x11000580 0x00 0x100>;
			interrupts = <0x00 0x6f 0x08>;
			clocks = <0x2a 0x0a 0x2a 0x28>;
			clock-names = "main", "dma";
			clock-div = <0x05>;
			#address-cells = <0x01>;
			#size-cells = <0x00>;
			status = "disabled";
		};

		pwm@11006000 {
			compatible = "mediatek,mt6785-pwm", "mediatek,mt8183-pwm";
			reg = <0x00 0x11006000 0x00 0x1000>;
			#pwm-cells = <0x02>;
			interrupts = <0x00 0xc8 0x08>;
			clocks = <0x2a 0x13 0x2a 0x0e 0x2a 0x0f 0x2a 0x10 0x2a 0x11 0x2a 0x12>;
			clock-names = "top", "main", "pwm1", "pwm2", "pwm3", "pwm4";
			status = "disabled";
		};

		i2c@11007000 {
			compatible = "mediatek,mt6785-i2c", "mediatek,mt8183-i2c";
			reg = <0x00 0x11007000 0x00 0x1000 0x00 0x11000080 0x00 0x80>;
			interrupts = <0x00 0x69 0x08>;
			clocks = <0x2a 0x0a 0x2a 0x28>;
			clock-names = "main", "dma";
			clock-div = <0x05>;
			#address-cells = <0x01>;
			#size-cells = <0x00>;
			status = "okay";
			clock-frequency = <0x61a80>;
			pinctrl-names = "default";
			pinctrl-0 = <0x37>;

			lm36274@11 {
				compatible = "ti,lm36274";
				reg = <0x11>;
				enable-gpios = <0x29 0x16 0x00>;
				pinctrl-names = "default";
				pinctrl-0 = <0x38>;

				regulators {
					compatible = "ti,lm36274-regulator";

					vboost {
						regulator-name = "backlight_vboost";
						regulator-max-microvolt = <0x6d19b0>;
						regulator-min-microvolt = "", "=\t";
						regulator-always-on;
					};

					vpos {
						regulator-name = "backlight_vddpos";
						regulator-max-microvolt = <0x632ea0>;
						regulator-min-microvolt = "", "=\t";
						phandle = <0x6e>;
					};

					vneg {
						regulator-name = "backlight_vddneg";
						regulator-max-microvolt = <0x632ea0>;
						regulator-min-microvolt = "", "=\t";
						phandle = <0x6f>;
					};
				};

				backlight {
					compatible = "ti,lm36274-backlight";
					phandle = <0x6d>;

					led {
						default-brightness = <0x320>;
						led-sources = <0x00 0x01 0x02>;
						max-brightness = <0x757>;
						ti,exponential-mode;
						ti,ovp-microvolt = <0x1ba8140>;
						ti,ramp-time-us = <0x186a0>;
					};
				};
			};
		};

		i2c@11008000 {
			compatible = "mediatek,mt6785-i2c", "mediatek,mt8183-i2c";
			reg = <0x00 0x11008000 0x00 0x1000 0x00 0x11000100 0x00 0x80>;
			interrupts = <0x00 0x6a 0x08>;
			clocks = <0x2a 0x0a 0x2a 0x28>;
			clock-names = "main", "dma";
			clock-div = <0x05>;
			#address-cells = <0x01>;
			#size-cells = <0x00>;
			status = "disabled";
		};

		i2c@11009000 {
			compatible = "mediatek,mt6785-i2c", "mediatek,mt8183-i2c";
			reg = <0x00 0x11009000 0x00 0x1000 0x00 0x11000180 0x00 0x180>;
			interrupts = <0x00 0x6b 0x08>;
			clocks = <0x2a 0x0a 0x2a 0x28>;
			clock-names = "main", "dma";
			clock-div = <0x05>;
			#address-cells = <0x01>;
			#size-cells = <0x00>;
			status = "disabled";
		};

		spi@1100a000 {
			compatible = "mediatek,mt6785-spi", "mediatek,mt6765-spi";
			#address-cells = <0x01>;
			#size-cells = <0x00>;
			reg = <0x00 0x1100a000 0x00 0x1000>;
			interrupts = <0x00 0x8f 0x08>;
			clocks = <0x03 0x0a 0x03 0x51 0x2a 0x1b>;
			clock-names = "parent-clk", "sel-clk", "spi-clk";
			status = "disabled";
		};

		pwm@1100e000 {
			compatible = "mediatek,mt6785-disp-pwm", "mediatek,mt8183-disp-pwm";
			reg = <0x00 0x1100e000 0x00 0x1000>;
			interrupts = <0x00 0x97 0x08>;
			#pwm-cells = <0x02>;
			clocks = <0x03 0x5c 0x2a 0x35>;
			clock-names = "main", "mm";
			status = "disabled";
		};

		i2c@1100f000 {
			compatible = "mediatek,mt6785-i2c", "mediatek,mt8183-i2c";
			reg = <0x00 0x1100f000 0x00 0x1000 0x00 0x11000300 0x00 0x80>;
			interrupts = <0x00 0x6c 0x08>;
			clocks = <0x2a 0x0a 0x2a 0x28>;
			clock-names = "main", "dma";
			clock-div = <0x05>;
			#address-cells = <0x01>;
			#size-cells = <0x00>;
			status = "okay";
			clock-frequency = <0x61a80>;
			pinctrl-names = "default";
			pinctrl-0 = <0x39>;

			nfc@28 {
				compatible = "nxp,nxp-nci-i2c";
				reg = <0x28>;
				interrupts-extended = <0x29 0x58 0x02>;
				enable-gpios = <0x29 0xa8 0x00>;
				firmware-gpios = <0x29 0x57 0x00>;
			};
		};

		spi@11010000 {
			compatible = "mediatek,mt6785-spi", "mediatek,mt6765-spi";
			#address-cells = <0x01>;
			#size-cells = <0x00>;
			reg = <0x00 0x11010000 0x00 0x1000>;
			interrupts = <0x00 0x93 0x08>;
			clocks = <0x03 0x0a 0x03 0x51 0x2a 0x37>;
			clock-names = "parent-clk", "sel-clk", "spi-clk";
			status = "disabled";
		};

		i2c@11011000 {
			compatible = "mediatek,mt6785-i2c", "mediatek,mt8183-i2c";
			reg = <0x00 0x11011000 0x00 0x1000 0x00 0x11000380 0x00 0x180>;
			interrupts = <0x00 0x6d 0x08>;
			clocks = <0x2a 0x0a 0x2a 0x28>;
			clock-names = "main", "dma";
			clock-div = <0x05>;
			#address-cells = <0x01>;
			#size-cells = <0x00>;
			status = "disabled";
		};

		spi@11012000 {
			compatible = "mediatek,mt6785-spi", "mediatek,mt6765-spi";
			#address-cells = <0x01>;
			#size-cells = <0x00>;
			reg = <0x00 0x11012000 0x00 0x1000>;
			interrupts = <0x00 0x98 0x08>;
			clocks = <0x03 0x0a 0x03 0x51 0x2a 0x3a>;
			clock-names = "parent-clk", "sel-clk", "spi-clk";
			status = "okay";
			mediatek,pad-select = <0x00>;
			pinctrl-names = "default";
			pinctrl-0 = <0x3a>;

			imu@0 {
				compatible = "bosch,bmi120";
				reg = <0x00>;
				interrupts-extended = <0x29 0x0a 0x01>;
				interrupt-names = "INT1";
				spi-cs-setup-delay-ns = <0xf4240>;
				spi-max-frequency = <0x989680>;
				vdd-supply = <0x3b>;
				vddio-supply = <0x3b>;
				pinctrl-names = "default";
				pinctrl-0 = <0x3c>;
				mount-matrix = "0", "1", "0", "-1", "0", "0", "0", "0", "1";
			};
		};

		spi@11013000 {
			compatible = "mediatek,mt6785-spi", "mediatek,mt6765-spi";
			#address-cells = <0x01>;
			#size-cells = <0x00>;
			reg = <0x00 0x11013000 0x00 0x1000>;
			interrupts = <0x00 0x99 0x08>;
			clocks = <0x03 0x0a 0x03 0x51 0x2a 0x3b>;
			clock-names = "parent-clk", "sel-clk", "spi-clk";
			status = "disabled";
		};

		i2c@11015000 {
			compatible = "mediatek,mt6785-i2c", "mediatek,mt8183-i2c";
			reg = <0x00 0x11015000 0x00 0x1000 0x00 0x11000800 0x00 0x80>;
			interrupts = <0x00 0x72 0x08>;
			clocks = <0x2a 0x0a 0x2a 0x28>;
			clock-names = "main", "dma";
			clock-div = <0x05>;
			#address-cells = <0x01>;
			#size-cells = <0x00>;
			status = "disabled";
		};

		i2c@11016000 {
			compatible = "mediatek,mt6785-i2c", "mediatek,mt8183-i2c";
			reg = <0x00 0x11016000 0x00 0x1000 0x00 0x11000500 0x00 0x80>;
			interrupts = <0x00 0x6e 0x08>;
			clocks = <0x2a 0x0a 0x2a 0x28>;
			clock-names = "main", "dma";
			clock-div = <0x05>;
			#address-cells = <0x01>;
			#size-cells = <0x00>;
			status = "okay";
			clock-frequency = <0x33e140>;
			pinctrl-names = "default";
			pinctrl-0 = <0x3d>;

			pmic@34 {
				compatible = "mediatek,mt6360";
				reg = <0x34>;
				interrupts-extended = <0x29 0x10 0x02>;
				interrupt-names = "IRQB";
				interrupt-controller;
				#interrupt-cells = <0x01>;
				pinctrl-names = "default";
				pinctrl-0 = <0x3e>;

				adc {
					compatible = "mediatek,mt6360-adc";
					#io-channel-cells = <0x01>;
				};

				charger {
					compatible = "mediatek,mt6360-chg";
					richtek,vinovp-microvolt = <0xdd40a0>;

					usb-otg-vbus-regulator {
						regulator-name = "usb-otg-vbus";
						regulator-max-microvolt = <0x58e1e8>;
						regulator-min-microvolt = <0x438528>;
						phandle = <0x47>;
					};
				};

				led-controller {
					compatible = "mediatek,mt6360-led";
					#address-cells = <0x01>;
					#size-cells = <0x00>;

					led@0 {
						reg = <0x00>;
						color = <0x00>;
						function = "indicator";
						led-max-microamp = <0x5dc0>;
					};

					led@4 {
						reg = <0x04>;
						color = <0x00>;
						flash-max-microamp = <0x7a120>;
						flash-max-timeout-us = <0xfa000>;
						function = "flash";
						function-enumerator = <0x01>;
						led-max-microamp = <0x30d40>;
					};

					led@5 {
						reg = <0x05>;
						color = <0x00>;
						flash-max-microamp = <0x7a120>;
						flash-max-timeout-us = <0xfa000>;
						function = "flash";
						function-enumerator = <0x02>;
						led-max-microamp = <0x30d40>;
					};
				};

				regulator {
					compatible = "mediatek,mt6360-regulator";
					LDO_VIN3-supply = <0x3f>;

					buck1 {
						regulator-name = "vapu";
						regulator-min-microvolt = <0x493e0>;
						regulator-max-microvolt = <0x13d620>;
						regulator-allowed-modes = <0x00 0x02 0x03>;
					};

					buck2 {
						regulator-name = "vdram1";
						regulator-min-microvolt = <0x493e0>;
						regulator-max-microvolt = <0x13d620>;
						regulator-allowed-modes = <0x00 0x02 0x03>;
						phandle = <0x3f>;
					};

					ldo1 {
						regulator-name = "vfp";
						regulator-min-microvolt = <0x124f80>;
						regulator-max-microvolt = <0x36ee80>;
						regulator-allowed-modes = <0x00 0x02>;
					};

					ldo2 {
						regulator-name = "vtp";
						regulator-min-microvolt = <0x2dc6c0>;
						regulator-max-microvolt = <0x2dc6c0>;
						regulator-allowed-modes = <0x00 0x02>;
						regulator-always-on;
						regulator-boot-on;
						phandle = <0x1f0>;
					};

					ldo3 {
						regulator-name = "vmc";
						regulator-min-microvolt = <0x124f80>;
						regulator-max-microvolt = <0x36ee80>;
						regulator-allowed-modes = <0x00 0x02>;
						phandle = <0x4b>;
					};

					ldo5 {
						regulator-name = "vmch";
						regulator-min-microvolt = <0x2932e0>;
						regulator-max-microvolt = <0x36ee80>;
						regulator-allowed-modes = <0x00 0x02>;
						phandle = <0x4a>;
					};

					ldo6 {
						regulator-name = "vmddr";
						regulator-min-microvolt = <0x7a120>;
						regulator-max-microvolt = <0x200b20>;
						regulator-allowed-modes = <0x00 0x02>;
						regulator-always-on;
					};

					ldo7 {
						regulator-name = "vdram2";
						regulator-min-microvolt = <0x7a120>;
						regulator-max-microvolt = <0x200b20>;
						regulator-allowed-modes = <0x00 0x02>;
						regulator-always-on;
					};
				};

				tcpc {
					compatible = "mediatek,mt6360-tcpc";
					interrupts-extended = <0x29 0x07 0x02>;
					interrupt-names = "PD_IRQB";

					connector {
						compatible = "usb-c-connector";
						label = "USB-C";
						data-role = "dual";
						op-sink-microwatt = <0x989680>;
						power-role = "dual";
						try-power-role = "sink";
						source-pdos = <0x22019096>;
						sink-pdos = <0x220190c8>;

						port {

							endpoint {
								remote-endpoint = <0x40>;
								phandle = <0x49>;
							};
						};
					};
				};
			};
		};

		spi@11018000 {
			compatible = "mediatek,mt6785-spi", "mediatek,mt6765-spi";
			#address-cells = <0x01>;
			#size-cells = <0x00>;
			reg = <0x00 0x11018000 0x00 0x1000>;
			interrupts = <0x00 0x9c 0x08>;
			clocks = <0x03 0x0a 0x03 0x51 0x2a 0x4a>;
			clock-names = "parent-clk", "sel-clk", "spi-clk";
			status = "disabled";
		};

		spi@11019000 {
			compatible = "mediatek,mt6785-spi", "mediatek,mt6765-spi";
			#address-cells = <0x01>;
			#size-cells = <0x00>;
			reg = <0x00 0x11019000 0x00 0x1000>;
			interrupts = <0x00 0x9d 0x08>;
			clocks = <0x03 0x0a 0x03 0x51 0x2a 0x4b>;
			clock-names = "parent-clk", "sel-clk", "spi-clk";
			status = "okay";
			mediatek,pad-select = <0x00>;
			pinctrl-names = "default";
			pinctrl-0 = <0x41>;

			touchscreen@0 {
				compatible = "novatek,nt36672a-ts";
				reg = <0x00>;
				firmware-name = "novatek/nt36672a_begonia_csot.bin";
				interrupts-extended = <0x29 0x01 0x01>;
				reset-gpios = <0x29 0x02 0x00>;
				panel = <0x42>;
				spi-cs-setup-delay-ns = <0x14>;
				spi-max-frequency = <0xf4240>;
				pinctrl-names = "default";
				pinctrl-0 = <0x43>;
				vcc-supply = <0x1f0>;
				iovcc-supply = <0x3b>;
			};
		};

		i2c@1101a000 {
			compatible = "mediatek,mt6785-i2c", "mediatek,mt8183-i2c";
			reg = <0x00 0x1101a000 0x00 0x1000 0x00 0x11000680 0x00 0x100>;
			interrupts = <0x00 0x70 0x08>;
			clocks = <0x2a 0x0a 0x2a 0x28>;
			clock-names = "main", "dma";
			clock-div = <0x05>;
			#address-cells = <0x01>;
			#size-cells = <0x00>;
			status = "disabled";
		};

		i2c@1101b000 {
			compatible = "mediatek,mt6785-i2c", "mediatek,mt8183-i2c";
			reg = <0x00 0x1101b000 0x00 0x1000 0x00 0x11000780 0x00 0x80>;
			interrupts = <0x00 0x71 0x08>;
			clocks = <0x2a 0x0a 0x2a 0x28>;
			clock-names = "main", "dma";
			clock-div = <0x05>;
			#address-cells = <0x01>;
			#size-cells = <0x00>;
			status = "disabled";
		};

		spi@1101d000 {
			compatible = "mediatek,mt6785-spi", "mediatek,mt6765-spi";
			#address-cells = <0x01>;
			#size-cells = <0x00>;
			reg = <0x00 0x1101d000 0x00 0x1000>;
			interrupts = <0x00 0x90 0x08>;
			clocks = <0x03 0x0a 0x03 0x51 0x2a 0x69>;
			clock-names = "parent-clk", "sel-clk", "spi-clk";
			status = "disabled";
		};

		spi@1101e000 {
			compatible = "mediatek,mt6785-spi", "mediatek,mt6765-spi";
			#address-cells = <0x01>;
			#size-cells = <0x00>;
			reg = <0x00 0x1101e000 0x00 0x1000>;
			interrupts = <0x00 0x91 0x08>;
			clocks = <0x03 0x0a 0x03 0x51 0x2a 0x6a>;
			clock-names = "parent-clk", "sel-clk", "spi-clk";
			status = "disabled";
		};

		usb@11201000 {
			compatible = "mediatek,mt6785-mtu3", "mediatek,mtu3";
			reg = <0x00 0x11201000 0x00 0x2e00 0x00 0x11203e00 0x00 0x100>;
			reg-names = "mac", "ippc";
			ranges = <0x00 0x00 0x00 0x11200000 0x00 0x3f00>;
			#address-cells = <0x02>;
			#size-cells = <0x02>;
			interrupts = <0x00 0x60 0x08>;
			clocks = <0x2a 0x34 0x2a 0x50>;
			clock-names = "sys_ck", "ref_ck";
			phys = <0x44 0x03 0x45 0x04>;
			wakeup-source;
			mediatek,syscon-wakeup = <0x46 0x420 0x65>;
			status = "okay";
			maximum-speed = "high-speed";
			usb-role-switch;
			vbus-supply = <0x47>;
			vusb33-supply = <0x48>;

			usb@0 {
				compatible = "mediatek,mt6785-xhci", "mediatek,mtk-xhci";
				reg = <0x00 0x00 0x00 0x1000>;
				reg-names = "mac";
				interrupts = <0x00 0x61 0x08>;
				clocks = <0x2a 0x50>;
				clock-names = "sys_ck";
				status = "okay";
				vusb33-supply = <0x48>;
			};

			port {

				endpoint {
					remote-endpoint = <0x49>;
					phandle = <0x40>;
				};
			};
		};

		clock-controller@11210000 {
			compatible = "mediatek,mt6785-audsys", "syscon";
			reg = <0x00 0x11210000 0x00 0x2000>;
			#clock-cells = <0x01>;
		};

		mmc@11230000 {
			compatible = "mediatek,mt6785-mmc", "mediatek,mt8183-mmc";
			reg = <0x00 0x11230000 0x00 0x1000 0x00 0x11f50000 0x00 0x1000>;
			interrupts = <0x00 0x65 0x08>;
			clocks = <0x03 0x53 0x2a 0x1c 0x2a 0x1e>;
			clock-names = "source", "hclk", "source_cg";
			status = "disabled";
		};

		mmc@11240000 {
			compatible = "mediatek,mt6785-mmc", "mediatek,mt8183-mmc";
			reg = <0x00 0x11240000 0x00 0x1000 0x00 0x11e10000 0x00 0x1000>;
			interrupts = <0x00 0x66 0x08>;
			clocks = <0x03 0x54 0x2a 0x1d 0x2a 0x27>;
			clock-names = "source", "hclk", "source_cg";
			status = "okay";
			bus-width = <0x04>;
			cd-gpios = <0x29 0x08 0x00>;
			max-frequency = <0xbebc200>;
			cap-sd-highspeed;
			disable-wp;
			no-mmc;
			no-sdio;
			sd-uhs-ddr50;
			sd-uhs-sdr104;
			sd-uhs-sdr50;
			vmmc-supply = <0x4a>;
			vqmmc-supply = <0x4b>;
			pinctrl-names = "default", "state_uhs";
			pinctrl-0 = <0x4c 0x4d>;
			pinctrl-1 = <0x4c>;
		};

		ufshci@11270000 {
			compatible = "mediatek,mt6785-ufshci";
			reg = <0x00 0x11270000 0x00 0x2300>;
			interrupts = <0x00 0x68 0x08>;
			phys = <0x4e>;
			clocks = <0x2a 0x4d 0x2a 0x55 0x2a 0x4f 0x2a 0x41 0x2a 0x3d>;
			clock-names = "ufs", "ufs-axi", "ufs-tick", "unipro-mbist", "unipro-tick";
			freq-table-hz = <0x00 0x00 0x00 0x00 0x00 0x00 0x00 0x00 0x00 0x00>;
			resets = <0x2a 0x01 0x2a 0x03 0x2a 0x05>;
			reset-names = "hci_rst", "unipro_rst", "crypto_rst";
			status = "okay";
			mediatek,ufs-disable-mcq;
			mediatek,ufs-support-va09;
			va09-supply = <0x4f>;
			vcc-supply = <0x50>;
			vccq2-supply = <0x51>;
		};

		t-phy@11e40000 {
			compatible = "mediatek,mt6785-tphy", "mediatek,generic-tphy-v2";
			#address-cells = <0x01>;
			#size-cells = <0x01>;
			ranges = <0x00 0x00 0x11e40000 0x1000>;

			usb-phy@0 {
				reg = <0x00 0x700>;
				clocks = <0x25>;
				clock-names = "ref";
				#phy-cells = <0x01>;
				phandle = <0x44>;
			};

			usb-phy@700 {
				reg = <0x700 0x900>;
				clocks = <0x25>;
				clock-names = "ref";
				#phy-cells = <0x01>;
				phandle = <0x45>;
			};
		};

		dsi-phy@11e50000 {
			compatible = "mediatek,mt8183-mipi-tx";
			reg = <0x00 0x11e50000 0x00 0x1000>;
			clocks = <0x52 0x16>;
			#clock-cells = <0x00>;
			#phy-cells = <0x00>;
			clock-output-names = "mipi_tx0_pll";
			status = "okay";
			phandle = <0x6a>;
		};

		ufs-phy@11fa0000 {
			compatible = "mediatek,mt6785-ufsphy", "mediatek,mt8183-ufsphy";
			reg = <0x00 0x11fa0000 0x00 0xc000>;
			clocks = <0x2a 0x3c 0x2a 0x3e>;
			clock-names = "unipro", "mp";
			#phy-cells = <0x00>;
			status = "okay";
			phandle = <0x4e>;
		};

		gpu@13040000 {
			compatible = "mediatek,mt6785-mali", "arm,mali-bifrost";
			reg = <0x00 0x13040000 0x00 0x4000>;
			clocks = <0x53 0x00>;
			interrupts = <0x00 0x137 0x08 0x00 0x136 0x08 0x00 0x135 0x08 0x00 0x138 0x08>;
			interrupt-names = "job", "mmu", "gpu", "event";
			operating-points-v2 = <0x54>;
			power-domains = <0x55 0x07 0x55 0x08 0x55 0x09 0x55 0x0a>;
			power-domain-names = "core0", "core1", "core2", "core3";
			#cooling-cells = <0x02>;
			status = "okay";
			mali-supply = <0x2c>;
		};

		clock-controller@13fbf000 {
			compatible = "mediatek,mt6785-mfgcfg", "syscon";
			reg = <0x00 0x13fbf000 0x00 0x1000>;
			#clock-cells = <0x01>;
			power-domains = <0x55 0x05>;
			phandle = <0x53>;
		};

		syscon@14000000 {
			compatible = "mediatek,mt6785-mmsys", "syscon";
			reg = <0x00 0x14000000 0x00 0x1000>;
			#clock-cells = <0x01>;
			#reset-cells = <0x01>;
			mboxes = <0x56 0x00 0x07 0x56 0x01 0x07>;
			mediatek,gce-client-reg = <0x56 0x01 0x00 0x1000>;
			phandle = <0x58>;

			port {
				#address-cells = <0x01>;
				#size-cells = <0x00>;

				endpoint@0 {
					reg = <0x00>;
					remote-endpoint = <0x57>;
					phandle = <0x5a>;
				};
			};
		};

		ovl@14008000 {
			compatible = "mediatek,mt6785-disp-ovl", "mediatek,mt8192-disp-ovl";
			reg = <0x00 0x14008000 0x00 0x1000>;
			clocks = <0x58 0x14>;
			interrupts = <0x00 0xf9 0x08>;
			iommus = <0x59 0x03 0x59 0x01>;
			power-domains = <0x55 0x0b>;
			mediatek,gce-client-reg = <0x56 0x01 0x8000 0x1000>;
			resets = <0x58 0x0d>;

			ports {
				#address-cells = <0x01>;
				#size-cells = <0x00>;

				port@0 {
					reg = <0x00>;

					endpoint {
						remote-endpoint = <0x5a>;
						phandle = <0x57>;
					};
				};

				port@1 {
					reg = <0x01>;

					endpoint {
						remote-endpoint = <0x5b>;
						phandle = <0x5c>;
					};
				};
			};
		};

		ovl@14009000 {
			compatible = "mediatek,mt6785-disp-ovl-2l", "mediatek,mt8192-disp-ovl-2l";
			reg = <0x00 0x14009000 0x00 0x1000>;
			clocks = <0x58 0x15>;
			interrupts = <0x00 0xfa 0x08>;
			iommus = <0x59 0x22 0x59 0x20>;
			power-domains = <0x55 0x0b>;
			mediatek,gce-client-reg = <0x56 0x01 0x9000 0x1000>;
			resets = <0x58 0x0e>;

			ports {
				#address-cells = <0x01>;
				#size-cells = <0x00>;

				port@0 {
					reg = <0x00>;

					endpoint {
						remote-endpoint = <0x5c>;
						phandle = <0x5b>;
					};
				};

				port@1 {
					reg = <0x01>;

					endpoint {
						remote-endpoint = <0x5d>;
						phandle = <0x5e>;
					};
				};
			};
		};

		ovl@1400a000 {
			compatible = "mediatek,mt6785-disp-ovl-2l", "mediatek,mt8192-disp-ovl-2l";
			reg = <0x00 0x1400a000 0x00 0x1000>;
			clocks = <0x58 0x16>;
			interrupts = <0x00 0xfb 0x08>;
			iommus = <0x59 0x23>;
			power-domains = <0x55 0x0b>;
			mediatek,gce-client-reg = <0x56 0x01 0xa000 0x1000>;
		};

		rdma@1400b000 {
			compatible = "mediatek,mt6785-disp-rdma", "mediatek,mt8183-disp-rdma";
			reg = <0x00 0x1400b000 0x00 0x1000>;
			clocks = <0x58 0x17>;
			interrupts = <0x00 0xfc 0x08>;
			iommus = <0x59 0x06>;
			power-domains = <0x55 0x0b>;
			mediatek,rdma-fifo-size = <0x1400>;
			mediatek,gce-client-reg = <0x56 0x01 0xb000 0x1000>;

			ports {
				#address-cells = <0x01>;
				#size-cells = <0x00>;

				port@0 {
					reg = <0x00>;

					endpoint {
						remote-endpoint = <0x5e>;
						phandle = <0x5d>;
					};
				};

				port@1 {
					reg = <0x01>;

					endpoint {
						remote-endpoint = <0x5f>;
						phandle = <0x60>;
					};
				};
			};
		};

		rdma@1400c000 {
			compatible = "mediatek,mt6785-disp-rdma", "mediatek,mt8183-disp-rdma";
			reg = <0x00 0x1400c000 0x00 0x1000>;
			clocks = <0x58 0x18>;
			interrupts = <0x00 0xfd 0x08>;
			iommus = <0x59 0x24>;
			power-domains = <0x55 0x0b>;
			mediatek,rdma-fifo-size = <0x800>;
			mediatek,gce-client-reg = <0x56 0x01 0xc000 0x1000>;
		};

		color@1400e000 {
			compatible = "mediatek,mt6785-disp-color", "mediatek,mt8173-disp-color";
			reg = <0x00 0x1400e000 0x00 0x1000>;
			clocks = <0x58 0x1a>;
			interrupts = <0x00 0xff 0x08>;
			power-domains = <0x55 0x0b>;
			mediatek,gce-client-reg = <0x56 0x01 0xe000 0x1000>;

			ports {
				#address-cells = <0x01>;
				#size-cells = <0x00>;

				port@0 {
					reg = <0x00>;

					endpoint {
						remote-endpoint = <0x60>;
						phandle = <0x5f>;
					};
				};

				port@1 {
					reg = <0x01>;

					endpoint {
						remote-endpoint = <0x61>;
						phandle = <0x62>;
					};
				};
			};
		};

		ccorr@1400f000 {
			compatible = "mediatek,mt6785-disp-ccorr", "mediatek,mt8192-disp-ccorr";
			reg = <0x00 0x1400f000 0x00 0x1000>;
			clocks = <0x58 0x1b>;
			interrupts = <0x00 0x100 0x08>;
			power-domains = <0x55 0x0b>;
			mediatek,gce-client-reg = <0x56 0x01 0xf000 0x1000>;

			ports {
				#address-cells = <0x01>;
				#size-cells = <0x00>;

				port@0 {
					reg = <0x00>;

					endpoint {
						remote-endpoint = <0x62>;
						phandle = <0x61>;
					};
				};

				port@1 {
					reg = <0x01>;

					endpoint {
						remote-endpoint = <0x63>;
						phandle = <0x64>;
					};
				};
			};
		};

		aal@14010000 {
			compatible = "mediatek,mt6785-disp-aal", "mediatek,mt8183-disp-aal";
			reg = <0x00 0x14010000 0x00 0x1000>;
			clocks = <0x58 0x1c>;
			interrupts = <0x00 0x101 0x08>;
			power-domains = <0x55 0x0b>;
			mediatek,gce-client-reg = <0x56 0x02 0x00 0x1000>;

			ports {
				#address-cells = <0x01>;
				#size-cells = <0x00>;

				port@0 {
					reg = <0x00>;

					endpoint {
						remote-endpoint = <0x64>;
						phandle = <0x63>;
					};
				};

				port@1 {
					reg = <0x01>;

					endpoint {
						remote-endpoint = <0x65>;
						phandle = <0x66>;
					};
				};
			};
		};

		gamma@14011000 {
			compatible = "mediatek,mt6785-disp-gamma", "mediatek,mt8183-disp-gamma";
			reg = <0x00 0x14011000 0x00 0x1000>;
			clocks = <0x58 0x1d>;
			interrupts = <0x00 0x102 0x08>;
			power-domains = <0x55 0x0b>;
			mediatek,gce-client-reg = <0x56 0x02 0x1000 0x1000>;

			ports {
				#address-cells = <0x01>;
				#size-cells = <0x00>;

				port@0 {
					reg = <0x00>;

					endpoint {
						remote-endpoint = <0x66>;
						phandle = <0x65>;
					};
				};

				port@1 {
					reg = <0x01>;

					endpoint {
						remote-endpoint = <0x67>;
						phandle = <0x72>;
					};
				};
			};
		};

		dither@14012000 {
			compatible = "mediatek,mt6785-disp-dither", "mediatek,mt8183-disp-dither";
			reg = <0x00 0x14012000 0x00 0x1000>;
			clocks = <0x58 0x1e>;
			interrupts = <0x00 0x103 0x08>;
			power-domains = <0x55 0x0b>;
			mediatek,gce-client-reg = <0x56 0x02 0x2000 0x1000>;

			ports {
				#address-cells = <0x01>;
				#size-cells = <0x00>;

				port@0 {
					reg = <0x00>;

					endpoint {
						remote-endpoint = <0x68>;
						phandle = <0x73>;
					};
				};

				port@1 {
					reg = <0x01>;

					endpoint {
						remote-endpoint = <0x69>;
						phandle = <0x6b>;
					};
				};
			};
		};

		dsi@14014000 {
			compatible = "mediatek,mt6785-dsi", "mediatek,mt8183-dsi";
			reg = <0x00 0x14014000 0x00 0x1000>;
			clocks = <0x58 0x20 0x58 0x21 0x6a>;
			clock-names = "engine", "digital", "hs";
			interrupts = <0x00 0x104 0x08>;
			phys = <0x6a>;
			phy-names = "dphy";
			power-domains = <0x55 0x0b>;
			resets = <0x58 0x19>;
			status = "okay";
			#address-cells = <0x01>;
			#size-cells = <0x00>;

			ports {
				#address-cells = <0x01>;
				#size-cells = <0x00>;

				port@0 {
					reg = <0x00>;

					endpoint {
						remote-endpoint = <0x6b>;
						phandle = <0x69>;
					};
				};

				port@1 {
					reg = <0x01>;

					endpoint {
						remote-endpoint = <0x6c>;
						phandle = <0x71>;
					};
				};
			};

			panel@0 {
				compatible = "xiaomi,begonia-csot-nt36672a", "novatek,nt36672a";
				reg = <0x00>;
				backlight = <0x6d>;
				reset-gpios = <0x29 0x2c 0x01>;
				vddio-supply = <0x3b>;
				vddneg-supply = <0x6e>;
				vddpos-supply = <0x6f>;
				pinctrl-names = "default";
				pinctrl-0 = <0x70>;
				phandle = <0x42>;

				port {

					endpoint {
						remote-endpoint = <0x71>;
						phandle = <0x6c>;
					};
				};
			};
		};

		mutex@14016000 {
			compatible = "mediatek,mt6785-disp-mutex";
			reg = <0x00 0x14016000 0x00 0x1000>;
			interrupts = <0x00 0xf1 0x08>;
			power-domains = <0x55 0x0b>;
			mediatek,gce-events = <0x82 0x83>;
			mediatek,gce-client-reg = <0x56 0x02 0x6000 0x1000>;
		};

		larb@14017000 {
			compatible = "mediatek,mt6785-smi-larb";
			reg = <0x00 0x14017000 0x00 0x1000>;
			mediatek,smi = <0x2b>;
			mediatek,larb-id = <0x00>;
			clocks = <0x58 0x01 0x58 0x01>;
			clock-names = "apb", "smi";
			power-domains = <0x55 0x0b>;
			phandle = <0x31>;
		};

		larb@14018000 {
			compatible = "mediatek,mt6785-smi-larb";
			reg = <0x00 0x14018000 0x00 0x1000>;
			mediatek,smi = <0x2b>;
			mediatek,larb-id = <0x01>;
			clocks = <0x58 0x02 0x58 0x02>;
			clock-names = "apb", "smi";
			power-domains = <0x55 0x0b>;
			phandle = <0x32>;
		};

		smi@14019000 {
			compatible = "mediatek,mt6785-smi-common", "mediatek,mt6779-smi-common";
			reg = <0x00 0x14019000 0x00 0x1000>;
			clocks = <0x58 0x00 0x58 0x00 0x58 0x03 0x58 0x04>;
			clock-names = "apb", "smi", "gals0", "gals1";
			power-domains = <0x55 0x0b>;
			phandle = <0x2b>;
		};

		postmask@14021000 {
			compatible = "mediatek,mt6785-disp-postmask", "mediatek,mt8192-disp-postmask";
			reg = <0x00 0x14021000 0x00 0x1000>;
			clocks = <0x58 0x2e>;
			interrupts = <0x00 0x10c 0x08>;
			power-domains = <0x55 0x0b>;
			mediatek,gce-client-reg = <0x56 0x03 0x1000 0x1000>;

			ports {
				#address-cells = <0x01>;
				#size-cells = <0x00>;

				port@0 {
					reg = <0x00>;

					endpoint {
						remote-endpoint = <0x72>;
						phandle = <0x67>;
					};
				};

				port@1 {
					reg = <0x01>;

					endpoint {
						remote-endpoint = <0x73>;
						phandle = <0x68>;
					};
				};
			};
		};

		clock-controller@15020000 {
			compatible = "mediatek,mt6785-imgsys", "syscon";
			reg = <0x00 0x15020000 0x00 0x1000>;
			#clock-cells = <0x01>;
			phandle = <0x74>;
		};

		larb@15021000 {
			compatible = "mediatek,mt6785-smi-larb";
			reg = <0x00 0x15021000 0x00 0x1000>;
			mediatek,smi = <0x2b>;
			mediatek,larb-id = <0x05>;
			clocks = <0x74 0x00 0x74 0x00 0x58 0x07>;
			clock-names = "apb", "smi", "gals";
			power-domains = <0x55 0x03>;
			phandle = <0x35>;
		};

		clock-controller@16000000 {
			compatible = "mediatek,mt6785-vdecsys", "syscon";
			reg = <0x00 0x16000000 0x00 0x1000>;
			#clock-cells = <0x01>;
			phandle = <0x75>;
		};

		larb@16010000 {
			compatible = "mediatek,mt6785-smi-larb";
			reg = <0x00 0x16010000 0x00 0x1000>;
			mediatek,smi = <0x2b>;
			mediatek,larb-id = <0x02>;
			clocks = <0x75 0x00 0x75 0x01>;
			clock-names = "apb", "smi";
			power-domains = <0x55 0x0c>;
			phandle = <0x33>;
		};

		clock-controller@17000000 {
			compatible = "mediatek,mt6785-vencsys", "syscon";
			reg = <0x00 0x17000000 0x00 0x1000>;
			#clock-cells = <0x01>;
			phandle = <0x76>;
		};

		larb@17010000 {
			compatible = "mediatek,mt6785-smi-larb";
			reg = <0x00 0x17010000 0x00 0x1000>;
			mediatek,smi = <0x2b>;
			mediatek,larb-id = <0x03>;
			clocks = <0x76 0x00 0x76 0x00>;
			clock-names = "apb", "smi";
			power-domains = <0x55 0x0d>;
			phandle = <0x34>;
		};

		clock-controller@19000000 {
			compatible = "mediatek,mt6785-apu_conn", "syscon";
			reg = <0x00 0x19000000 0x00 0x1000>;
			#clock-cells = <0x01>;
		};

		clock-controller@19020000 {
			compatible = "mediatek,mt6785-apu_vcore", "syscon";
			reg = <0x00 0x19020000 0x00 0x1000>;
			#clock-cells = <0x01>;
		};

		clock-controller@19180000 {
			compatible = "mediatek,mt6785-apu_core0", "syscon";
			reg = <0x00 0x19180000 0x00 0x1000>;
			#clock-cells = <0x01>;
		};

		clock-controller@19280000 {
			compatible = "mediatek,mt6785-apu_core1", "syscon";
			reg = <0x00 0x19280000 0x00 0x1000>;
			#clock-cells = <0x01>;
		};

		clock-controller@1a000000 {
			compatible = "mediatek,mt6785-camsys", "syscon";
			reg = <0x00 0x1a000000 0x00 0x1000>;
			#clock-cells = <0x01>;
			phandle = <0x77>;
		};

		larb@1a001000 {
			compatible = "mediatek,mt6785-smi-larb";
			reg = <0x00 0x1a001000 0x00 0x1000>;
			mediatek,smi = <0x2b>;
			mediatek,larb-id = <0x06>;
			clocks = <0x77 0x00 0x77 0x00 0x58 0x08>;
			clock-names = "apb", "smi", "gals";
			power-domains = <0x55 0x01>;
			phandle = <0x36>;
		};
	};

	chosen {
		#address-cells = <0x02>;
		#size-cells = <0x02>;
		ranges;
		bootargs = [00];
	};

	haptic {
		compatible = "regulator-haptic";
		haptic-supply = <0x78>;
		max-microvolt = <0x2ab980>;
		min-microvolt = <0x124f80>;
	};

	i2c-sensors {
		compatible = "i2c-gpio";
		scl-gpios = <0x29 0x3d 0x06>;
		sda-gpios = <0x29 0x3e 0x06>;
		pinctrl-names = "default";
		pinctrl-0 = <0x79>;
		#address-cells = <0x01>;
		#size-cells = <0x00>;

		magnetometer@c {
			compatible = "asahi-kasei,ak09918";
			reg = <0x0c>;
			vdd-supply = <0x3b>;
		};

		proximity@47 {
			compatible = "sensortek,stk3310";
			reg = <0x47>;
			interrupts-extended = <0x29 0x06 0x02>;
			proximity-near-level = <0x46>;
			pinctrl-names = "default";
			pinctrl-0 = <0x7a>;
		};
	};

	reserved-memory {
		#address-cells = <0x02>;
		#size-cells = <0x02>;
		ranges;
	};

	scp {
		compatible = "mediatek,scp";
	};
};
